AUTOSAR XML (schema 4-3-0)
package /Dimmer
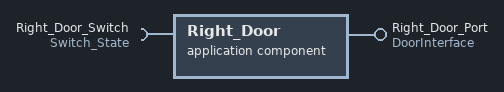
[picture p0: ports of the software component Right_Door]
  application sw component type Right_Door
    require port Right_Door_Switch: client-com-spec=getSwitchState, required-interface=Switch_State
    provide port Right_Door_Port: nonqueued-sender-com-spec=DoorStatus, provided-interface=DoorInterface
    behavior Right_Door_InternalBehavior
  swc implementation Right_Door_Implementation: behavior=Right_Door_InternalBehavior
